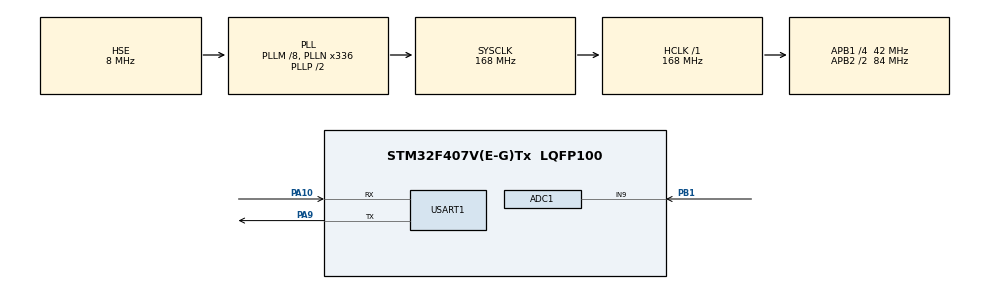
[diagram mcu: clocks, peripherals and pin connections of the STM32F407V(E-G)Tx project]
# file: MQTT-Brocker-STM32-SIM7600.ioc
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ADC1.Channel-0\#ChannelRegularConversion=ADC_CHANNEL_9
ADC1.ContinuousConvMode=ENABLE
ADC1.NbrOfConversionFlag=1
ADC1.Rank-0\#ChannelRegularConversion=1
ADC1.SamplingTime-0\#ChannelRegularConversion=ADC_SAMPLETIME_3CYCLES
ADC1.master=1
Mcu.Family=STM32F4
Mcu.Name=STM32F407V(E-G)Tx
Mcu.Package=LQFP100
NVIC.PriorityGroup=NVIC_PRIORITYGROUP_0
PA10.Mode=Asynchronous
PA10.Signal=USART1_RX
PA9.Mode=Asynchronous
PA9.Signal=USART1_TX
PB1.Signal=ADCx_IN9
ProjectManager.HeapSize=0x200
ProjectManager.StackSize=0x400
ProjectManager.TargetToolchain=STM32CubeIDE
RCC.48MHZClocksFreq_Value=48000000
RCC.AHBFreq_Value=168000000
RCC.APB1CLKDivider=RCC_HCLK_DIV4
RCC.APB1Freq_Value=42000000
RCC.APB1TimFreq_Value=84000000
RCC.APB2CLKDivider=RCC_HCLK_DIV2
RCC.APB2Freq_Value=84000000
RCC.APB2TimFreq_Value=168000000
RCC.CortexFreq_Value=168000000
RCC.HCLKFreq_Value=168000000
RCC.HSE_VALUE=8000000
RCC.HSI_VALUE=16000000
RCC.PLLM=8
RCC.PLLN=336
RCC.PLLQ=7
RCC.PLLSourceVirtual=RCC_PLLSOURCE_HSE
RCC.SYSCLKFreq_VALUE=168000000
RCC.SYSCLKSource=RCC_SYSCLKSOURCE_PLLCLK
RCC.VCOOutputFreq_Value=336000000
SH.ADCx_IN9.0=ADC1_IN9,IN9
USART1.VirtualMode=VM_ASYNC
board=STM32F407G-DISC1

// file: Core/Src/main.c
/* USER CODE BEGIN Header */
/**
  ******************************************************************************
  * @file           : main.c
  * @brief          : Main program body
  ******************************************************************************
  * @attention
  *
  * Copyright (c) 2023 STMicroelectronics.
  * All rights reserved.
  *
  * This software is licensed under terms that can be found in the LICENSE file
  * in the root directory of this software component.
  * If no LICENSE file comes with this software, it is provided AS-IS.
  *
  ******************************************************************************
  */
/* USER CODE END Header */
#include "main.h"

/* USER CODE BEGIN Includes */
#include <string.h>
#include <stdio.h>

/* USER CODE END Includes */

 ADC_HandleTypeDef hadc1;

UART_HandleTypeDef huart1;

void SystemClock_Config(void);
static void MX_GPIO_Init(void);
static void MX_ADC1_Init(void);
static void MX_USART1_UART_Init(void);

/* USER CODE BEGIN 0 */
const char apn[]  = "live.vodafone.com"; // Change this to your Provider details
const char host[] = "tcp://test.mosquitto.org"; // Change this to your host
const int  port = 1883;
const char username[] = "";
const char password[] = "";
const char topic[] = "pot/adc/1";
const uint32_t timeOut =10000;
char ATcommand[80];
uint8_t buffer[160] = {0};
uint8_t ATisOK = 0;
uint8_t CGREGisOK = 0;
uint32_t previousTick;
uint16_t readValue;
char charData[15];

void SIMTransmit(char *cmd)
{
  memset(buffer,0,sizeof(buffer));
  HAL_UART_Transmit(&huart1,(uint8_t *)cmd,strlen(cmd),1000);
  HAL_UART_Receive (&huart1, buffer, 100, 1000);
}

void mqttPublish(void)
{
  ATisOK = 0;
  CGREGisOK = 0;

  // Check for OK response for AT
  previousTick =  HAL_GetTick();
  while(!ATisOK && previousTick  + timeOut >  HAL_GetTick())
  {
    SIMTransmit("AT\r\n");
    HAL_Delay(1000);
    if(strstr((char *)buffer,"OK"))
    {
      ATisOK = 1;
    }
  }

  // Check for network registration.
  if(ATisOK)
  {
    previousTick =  HAL_GetTick();
    while(!CGREGisOK  && previousTick  + timeOut >  HAL_GetTick())
    {
      SIMTransmit("AT+CGREG?\r\n");
      if(strstr((char *)buffer,"+CGREG: 0,1")) // Use 0,5 For Roaming
      {
        CGREGisOK = 1;
      }
    }
  }

  // If registered
  if(CGREGisOK)
  {
	sprintf(ATcommand,"AT+CGSOCKCONT=1,\"IP\",\"%s\"\r\n",apn); // Specify the value of  PDP context
	SIMTransmit(ATcommand);
	SIMTransmit("AT+CMQTTSTART\r\n"); // Start MQTT Service
	SIMTransmit("AT+CMQTTACCQ=0,\"client01\"\r\n"); // Acquire a Client
	sprintf(ATcommand,"AT+CMQTTCONNECT=0,\"%s:%d\",60,1\r\n",host,port); // Connect to a MQTT Server
	// sprintf(ATcommand,"AT+CMQTTCONNECT=0,\"%s:%d\",60,1,%s,%s\r\n",host,port,username,password);
	SIMTransmit(ATcommand);
	sprintf(ATcommand,"AT+CMQTTTOPIC=0,%d\r\n",strlen(topic)); // Set the topic for publish message
	SIMTransmit(ATcommand);
	sprintf(ATcommand,"%s\r\n",topic);
	SIMTransmit(ATcommand);
	sprintf(ATcommand,"AT+CMQTTPAYLOAD=0,%d\r\n",strlen(charData)-2); // Set the payload
	SIMTransmit(ATcommand);
	SIMTransmit(charData);
	SIMTransmit("AT+CMQTTPUB=0,1,60\r\n"); // Publish
	SIMTransmit("AT+CMQTTDISC=0,120\r\n"); // Disconnect from Server
	SIMTransmit("AT+CMQTTREL=0\r\n"); // Release the Client
	SIMTransmit("AT+CMQTTSTOP\r\n"); // Stop MQTT Service
  }
}
/* USER CODE END 0 */

int main(void)
{

  /* MCU Configuration--------------------------------------------------------*/

  /* Reset of all peripherals, Initializes the Flash interface and the Systick. */
  HAL_Init();

  /* Configure the system clock */
  SystemClock_Config();

  /* Initialize all configured peripherals */
  MX_GPIO_Init();
  MX_ADC1_Init();
  MX_USART1_UART_Init();
  /* USER CODE BEGIN 2 */
  HAL_ADC_Start(&hadc1);

  /* USER CODE END 2 */

  /* Infinite loop */
  while (1)
  {

    /* USER CODE BEGIN 3 */
	  HAL_ADC_PollForConversion(&hadc1,1000);
	      readValue = HAL_ADC_GetValue(&hadc1);
	      sprintf(charData, "%d\r\n", readValue);
	      mqttPublish();
  }
  /* USER CODE END 3 */
}

void SystemClock_Config(void)
{
  RCC_OscInitTypeDef RCC_OscInitStruct = {0};
  RCC_ClkInitTypeDef RCC_ClkInitStruct = {0};

  /** Configure the main internal regulator output voltage
  */
  __HAL_RCC_PWR_CLK_ENABLE();
  __HAL_PWR_VOLTAGESCALING_CONFIG(PWR_REGULATOR_VOLTAGE_SCALE1);

  /** Initializes the RCC Oscillators according to the specified parameters
  * in the RCC_OscInitTypeDef structure.
  */
  RCC_OscInitStruct.OscillatorType = RCC_OSCILLATORTYPE_HSE;
  RCC_OscInitStruct.HSEState = RCC_HSE_OFF;
  RCC_OscInitStruct.PLL.PLLState = RCC_PLL_ON;
  RCC_OscInitStruct.PLL.PLLSource = RCC_PLLSOURCE_HSE;
  RCC_OscInitStruct.PLL.PLLM = 8;
  RCC_OscInitStruct.PLL.PLLN = 336;
  RCC_OscInitStruct.PLL.PLLP = RCC_PLLP_DIV2;
  RCC_OscInitStruct.PLL.PLLQ = 7;
  if (HAL_RCC_OscConfig(&RCC_OscInitStruct) != HAL_OK)
  {
    Error_Handler();
  }

  /** Initializes the CPU, AHB and APB buses clocks
  */
  RCC_ClkInitStruct.ClockType = RCC_CLOCKTYPE_HCLK|RCC_CLOCKTYPE_SYSCLK
                              |RCC_CLOCKTYPE_PCLK1|RCC_CLOCKTYPE_PCLK2;
  RCC_ClkInitStruct.SYSCLKSource = RCC_SYSCLKSOURCE_PLLCLK;
  RCC_ClkInitStruct.AHBCLKDivider = RCC_SYSCLK_DIV1;
  RCC_ClkInitStruct.APB1CLKDivider = RCC_HCLK_DIV4;
  RCC_ClkInitStruct.APB2CLKDivider = RCC_HCLK_DIV2;

  if (HAL_RCC_ClockConfig(&RCC_ClkInitStruct, FLASH_LATENCY_5) != HAL_OK)
  {
    Error_Handler();
  }
}

static void MX_ADC1_Init(void)
{

  ADC_ChannelConfTypeDef sConfig = {0};

  /** Configure the global features of the ADC (Clock, Resolution, Data Alignment and number of conversion)
  */
  hadc1.Instance = ADC1;
  hadc1.Init.ClockPrescaler = ADC_CLOCK_SYNC_PCLK_DIV4;
  hadc1.Init.Resolution = ADC_RESOLUTION_12B;
  hadc1.Init.ScanConvMode = DISABLE;
  hadc1.Init.ContinuousConvMode = ENABLE;
  hadc1.Init.DiscontinuousConvMode = DISABLE;
  hadc1.Init.ExternalTrigConvEdge = ADC_EXTERNALTRIGCONVEDGE_NONE;
  hadc1.Init.ExternalTrigConv = ADC_SOFTWARE_START;
  hadc1.Init.DataAlign = ADC_DATAALIGN_RIGHT;
  hadc1.Init.NbrOfConversion = 1;
  hadc1.Init.DMAContinuousRequests = DISABLE;
  hadc1.Init.EOCSelection = ADC_EOC_SINGLE_CONV;
  if (HAL_ADC_Init(&hadc1) != HAL_OK)
  {
    Error_Handler();
  }

  /** Configure for the selected ADC regular channel its corresponding rank in the sequencer and its sample time.
  */
  sConfig.Channel = ADC_CHANNEL_9;
  sConfig.Rank = 1;
  sConfig.SamplingTime = ADC_SAMPLETIME_3CYCLES;
  if (HAL_ADC_ConfigChannel(&hadc1, &sConfig) != HAL_OK)
  {
    Error_Handler();
  }

}

static void MX_USART1_UART_Init(void)
{

  huart1.Instance = USART1;
  huart1.Init.BaudRate = 115200;
  huart1.Init.WordLength = UART_WORDLENGTH_8B;
  huart1.Init.StopBits = UART_STOPBITS_1;
  huart1.Init.Parity = UART_PARITY_NONE;
  huart1.Init.Mode = UART_MODE_TX_RX;
  huart1.Init.HwFlowCtl = UART_HWCONTROL_NONE;
  huart1.Init.OverSampling = UART_OVERSAMPLING_16;
  if (HAL_UART_Init(&huart1) != HAL_OK)
  {
    Error_Handler();
  }

}

static void MX_GPIO_Init(void)
{

  /* GPIO Ports Clock Enable */
  __HAL_RCC_GPIOB_CLK_ENABLE();
  __HAL_RCC_GPIOA_CLK_ENABLE();

}

void Error_Handler(void)
{
  __disable_irq();
  while (1)
  {
  }
}
